AUTOSAR XML (schema 4-0-3)
standard types defined: Boolean, UInt32
package /AUTOSAR_Platform/DataConstrs
  range DC_Boolean: raw 0..1
package /PATAC/MSM/ComponentTypes
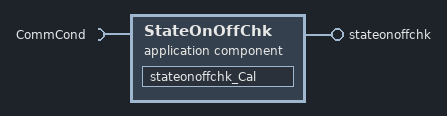
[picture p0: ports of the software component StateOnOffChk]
  application sw component type StateOnOffChk
    provide port stateonoffchk: server-com-spec{operation=Cal, queue-length=1}, provided-interface=stateonoffchk
    require port CommCond: nonqueued-receiver-com-spec{data-element=Val, filter=data-filter-type=ALWAYS, init-value=0}, required-interface=CommCond
    behavior StateOnOffChk_InternalBehavior
      operation invoked event OIT_stateonoffchk_Cal_stateonoffchk_Cal: start-on-event=stateonoffchk_Cal, operation=stateonoffchk.Cal
      runnable stateonoffchk_Cal
        data-receive-point-by-arguments:
          access REC_CommCond_Val: accessed-variable=CommCond.Val
  swc implementation StateOnOffChk_Implementation: behavior=StateOnOffChk_InternalBehavior
    code-descriptors:
      code Default: artifact-descriptors=autosar-engineering-object={short-label=Default, category=SWSRC}
package /PATAC/MSM/ModeAdjust/PortInterface
  client server interface stateonoffchk
    operation Cal
      arg modestate32: type=UInt32, direction=IN, server-argument-impl-policy=USE-ARGUMENT-TYPE
      arg modestateon: type=Boolean, direction=OUT, server-argument-impl-policy=USE-ARGUMENT-TYPE
  sender receiver interface CommCond: invalidation-policy{data-element=Val, handle-invalid=DONT-INVALIDATE}
    data Val: type=Boolean
